# STM32F091CBT6 register map
File version: 1.0
Registers are 32-bit, access not given, reset 0x0 unless marked. A register's access mark holds for its fields unless they carry their own. Offsets are from the block's base; [hi:lo] are bit positions; {n}, {i} and the like mark numbered series.

## CEC
Base 0x40007800
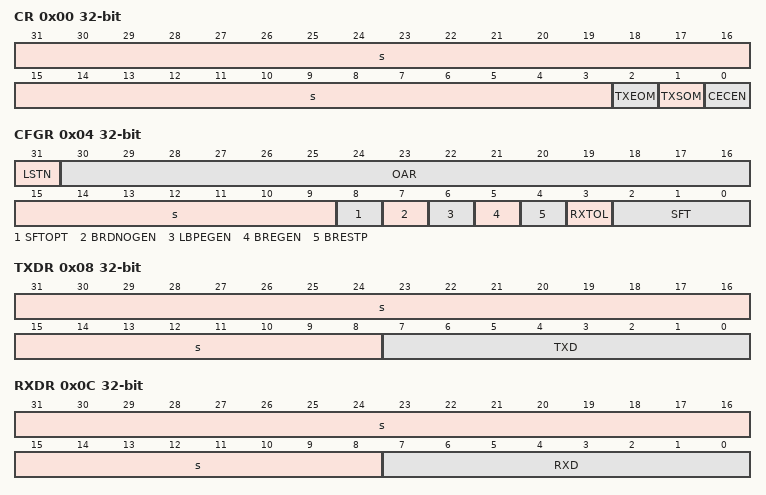
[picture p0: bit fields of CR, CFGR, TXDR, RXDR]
0x00 CR
  [31:3] s, [2] TXEOM, [1] TXSOM, [0] CECEN
0x04 CFGR
  [31] LSTN, [30:16] OAR, [15:9] s, [8] SFTOPT, [7] BRDNOGEN, [6] LBPEGEN, [5] BREGEN, [4] BRESTP, [3] RXTOL, [2:0] SFT
0x08 TXDR
  [31:8] s, [7:0] TXD
0x0C RXDR
  [31:8] s, [7:0] RXD
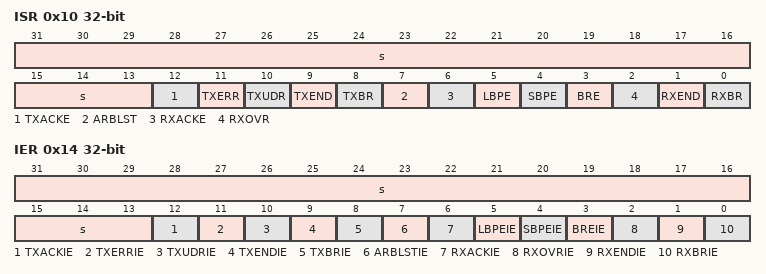
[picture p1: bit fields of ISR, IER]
0x10 ISR
  [31:13] s, [12] TXACKE, [11] TXERR, [10] TXUDR, [9] TXEND, [8] TXBR, [7] ARBLST, [6] RXACKE, [5] LBPE, [4] SBPE, [3] BRE, [2] RXOVR, [1] RXEND, [0] RXBR
0x14 IER
  [31:13] s, [12] TXACKIE, [11] TXERRIE, [10] TXUDRIE, [9] TXENDIE, [8] TXBRIE, [7] ARBLSTIE, [6] RXACKIE, [5] LBPEIE, [4] SBPEIE, [3] BREIE, [2] RXOVRIE, [1] RXENDIE, [0] RXBRIE

## SYSCFGCOMP
Base 0x40010000
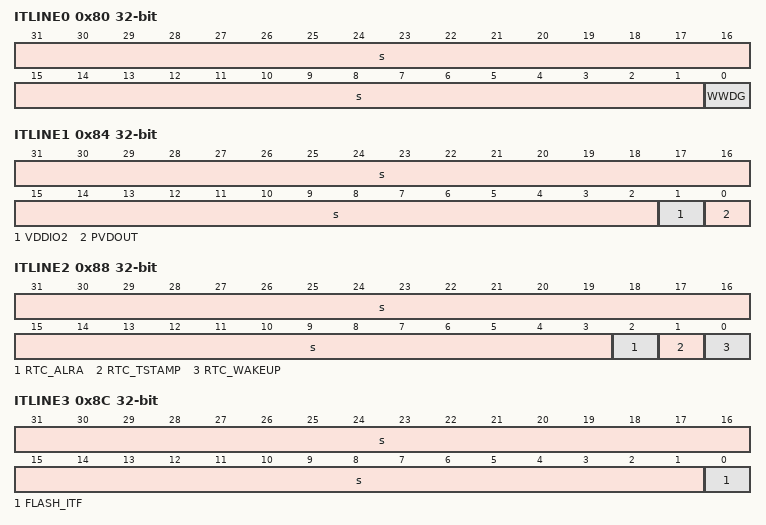
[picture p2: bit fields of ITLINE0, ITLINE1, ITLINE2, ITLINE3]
0x80 ITLINE0
  [31:1] s, [0] WWDG
0x84 ITLINE1
  [31:2] s, [1] VDDIO2, [0] PVDOUT
0x88 ITLINE2
  [31:3] s, [2] RTC_ALRA, [1] RTC_TSTAMP, [0] RTC_WAKEUP
0x8C ITLINE3
  [31:1] s, [0] FLASH_ITF
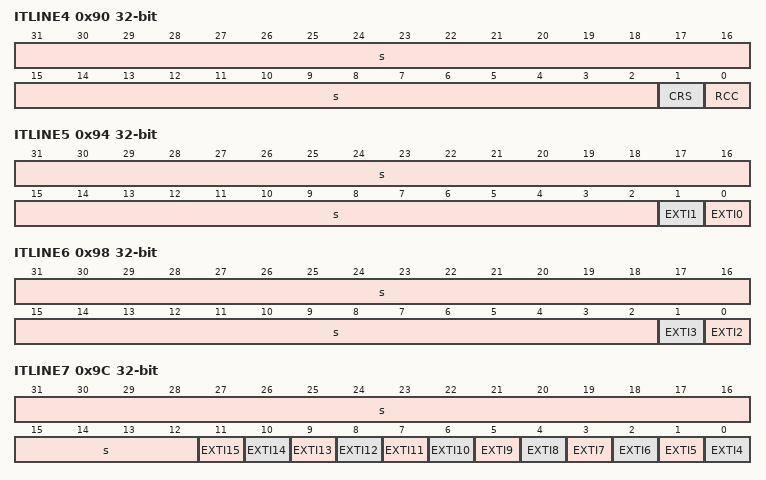
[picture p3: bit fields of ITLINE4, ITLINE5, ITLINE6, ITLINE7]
0x90 ITLINE4
  [31:2] s, [1] CRS, [0] RCC
0x94 ITLINE5
  [31:2] s, [1] EXTI1, [0] EXTI0
0x98 ITLINE6
  [31:2] s, [1] EXTI3, [0] EXTI2
0x9C ITLINE7
  [31:12] s, [n-4] EXTI{n} (n=4..15)
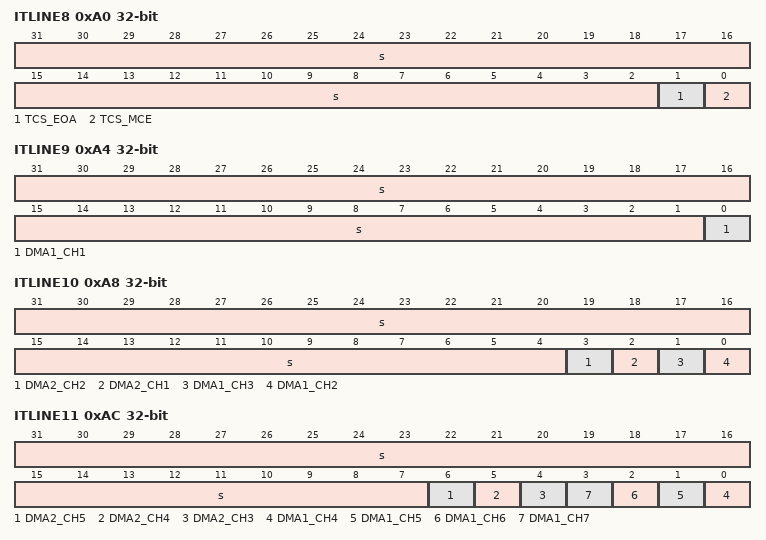
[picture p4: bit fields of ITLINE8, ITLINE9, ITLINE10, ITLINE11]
0xA0 ITLINE8
  [31:2] s, [1] TCS_EOA, [0] TCS_MCE
0xA4 ITLINE9
  [31:1] s, [0] DMA1_CH1
0xA8 ITLINE10
  [31:4] s, [3] DMA2_CH2, [2] DMA2_CH1, [1] DMA1_CH3, [0] DMA1_CH2
0xAC ITLINE11
  [31:7] s, [6] DMA2_CH5, [5] DMA2_CH4, [4] DMA2_CH3, [n-4] DMA1_CH{n} (n=4..7)
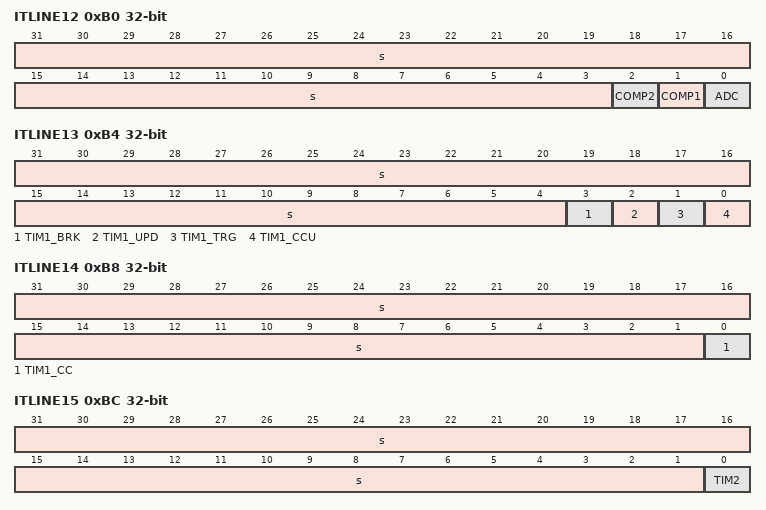
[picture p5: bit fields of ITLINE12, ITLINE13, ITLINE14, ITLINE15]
0xB0 ITLINE12
  [31:3] s, [2] COMP2, [1] COMP1, [0] ADC
0xB4 ITLINE13
  [31:4] s, [3] TIM1_BRK, [2] TIM1_UPD, [1] TIM1_TRG, [0] TIM1_CCU
0xB8 ITLINE14
  [31:1] s, [0] TIM1_CC
0xBC ITLINE15
  [31:1] s, [0] TIM2
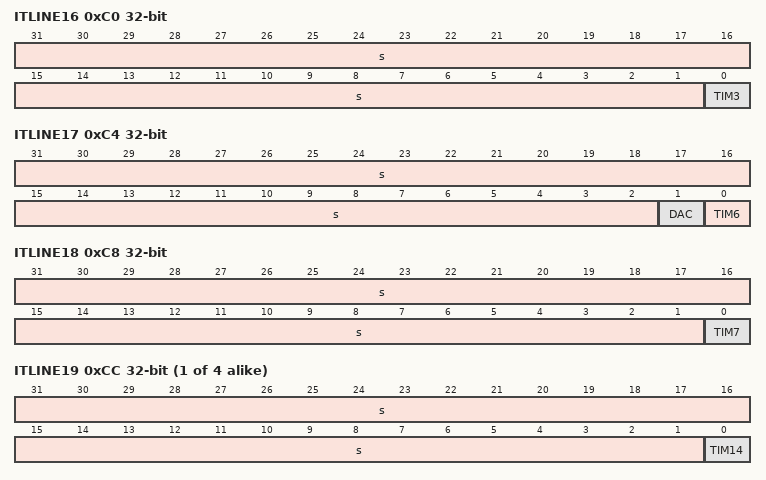
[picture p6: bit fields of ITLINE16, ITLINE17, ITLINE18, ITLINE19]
0xC0 ITLINE16
  [31:1] s, [0] TIM3
0xC4 ITLINE17
  [31:2] s, [1] DAC, [0] TIM6
0xC8 ITLINE18
  [31:1] s, [0] TIM7
{0x80+4i} ITLINE{i} (i=19..22)
  [31:1] s, [0] TIM{i-5}
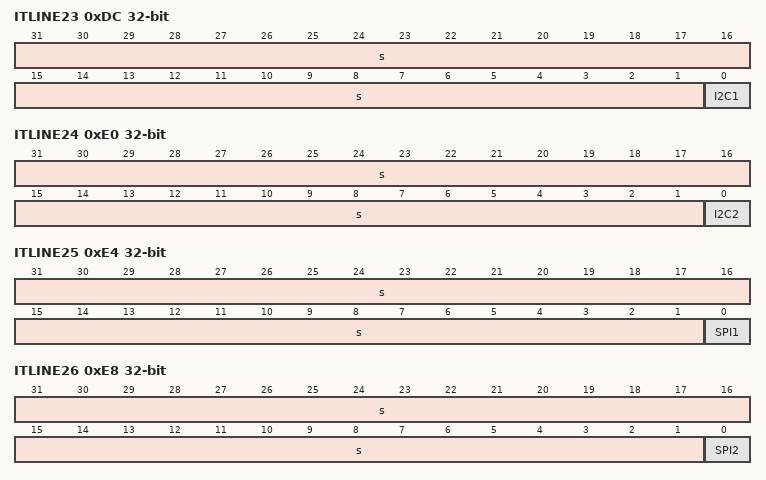
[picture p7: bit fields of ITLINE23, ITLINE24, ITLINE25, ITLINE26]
0xDC ITLINE23
  [31:1] s, [0] I2C1
0xE0 ITLINE24
  [31:1] s, [0] I2C2
0xE4 ITLINE25
  [31:1] s, [0] SPI1
0xE8 ITLINE26
  [31:1] s, [0] SPI2
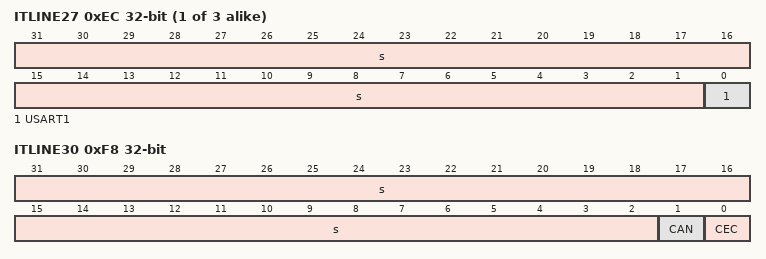
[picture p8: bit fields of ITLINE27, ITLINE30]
{0x80+4i} ITLINE{i} (i=27..29)
  [31:1] s, [0] USART{i-26}
0xF8 ITLINE30
  [31:2] s, [1] CAN, [0] CEC

## EXTI
Base 0x40010400
0x00 IMR
  [31:0] IM
0x04 EMR
  [31:0] EM
0x08 RTSR
  [31] RT31, [n] RT{n} (n=19..23), [30:18] s, [17:0] RT
0x0C FTSR
  [31] FT31, [n] FT{n} (n=19..23), [30:18] s, [17:0] FT
0x10 SWIER
  [31] SWI31, [n] SWI{n} (n=19..23), [30:18] s, [17:0] SWI
0x14 PR
  [31] PIF31, [n] PIF{n} (n=19..23), [30:18] s, [17:0] PIF

## ADC
Base 0x40012400
0x00 ISR
  [7] AWD, [31:5] s, [4] OVR, [3] EOSEQ, [2] EOC, [1] EOSMP, [0] ADRDY
0x04 IER
  [7] AWDIE, [31:5] s, [4] OVRIE, [3] EOSEQIE, [2] EOCIE, [1] EOSMPIE, [0] ADRDYIE
0x08 CR
  [31] ADCAL, [4] ADSTP, [30:3] s, [2] ADSTART, [1] ADDIS, [0] ADEN
0x0C CFGR1
  [30:26] AWDCH, [23] AWDEN, [22] AWDSGL, [16] DISCEN, [15] AUTOFF, [14] WAIT, [13] CONT, [12] OVRMOD, [11:10] EXTEN, [31:9] s, [8:6] EXTSEL, [5] ALIGN, [4:3] RES, [2] SCANDIR, [1] DMACFG, [0] DMAEN
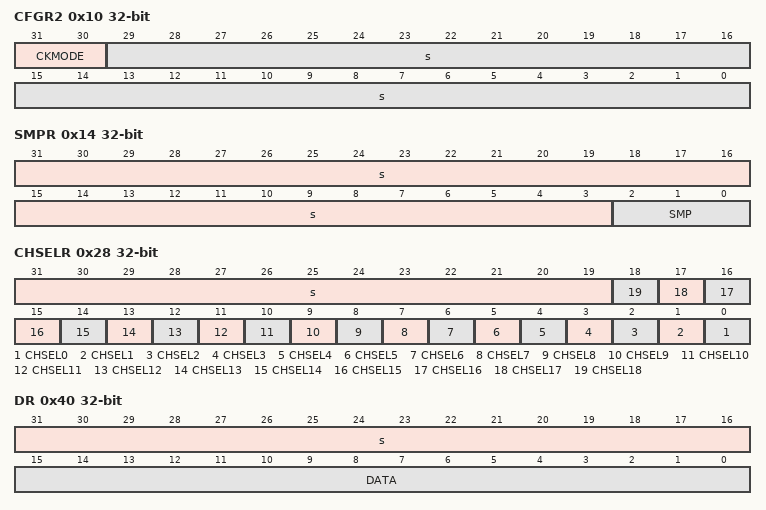
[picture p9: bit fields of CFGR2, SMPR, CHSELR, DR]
0x10 CFGR2
  [31:30] CKMODE, [29:0] s
0x14 SMPR
  [31:3] s, [2:0] SMP
0x20 TR
  [27:16] HT, [31:12] s, [11:0] LT
0x28 CHSELR
  [31:19] s, [n] CHSEL{n} (n=0..18)
0x40 DR
  [31:16] s, [15:0] DATA
0x308 CCR
  [24] VBATEN, [23] TSEN, [22] VREFEN, [31:0] s

## TIM1
Base 0x40012C00
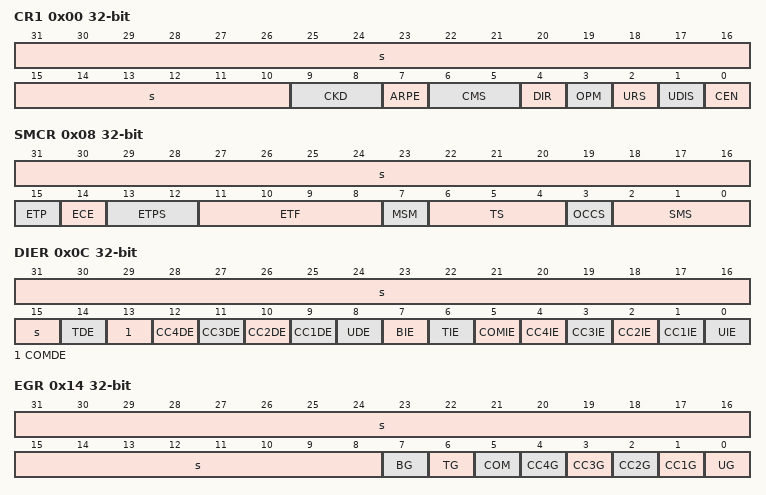
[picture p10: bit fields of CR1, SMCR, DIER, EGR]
0x00 CR1
  [31:10] s, [9:8] CKD, [7] ARPE, [6:5] CMS, [4] DIR, [3] OPM, [2] URS, [1] UDIS, [0] CEN
0x04 CR2
  [2n+6] OIS{n} (n=1..4), [13] OIS3N, [11] OIS2N, [9] OIS1N, [7] TI1S, [6:4] MMS, [3] CCDS, [2] CCUS, [31:1] s, [0] CCPC
0x08 SMCR
  [31:16] s, [15] ETP, [14] ECE, [13:12] ETPS, [11:8] ETF, [7] MSM, [6:4] TS, [3] OCCS, [2:0] SMS
0x0C DIER
  [31:15] s, [14] TDE, [13] COMDE, [n+8] CC{n}DE (n=1..4), [8] UDE, [7] BIE, [6] TIE, [5] COMIE, [n] CC{n}IE (n=1..4), [0] UIE
0x10 SR
  [n+8] CC{n}OF (n=1..4), [31:8] s, [7] BIF, [6] TIF, [5] COMIF, [n] CC{n}IF (n=1..4), [0] UIF
0x14 EGR
  [31:8] s, [7] BG, [6] TG, [5] COM, [n] CC{n}G (n=1..4), [0] UG
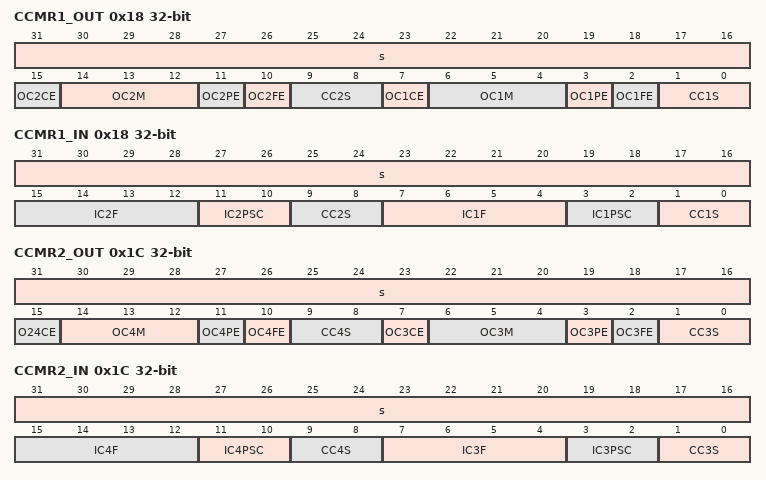
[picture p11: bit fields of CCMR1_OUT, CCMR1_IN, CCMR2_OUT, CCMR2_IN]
0x18 CCMR1_OUT
  [31:16] s, [15] OC2CE, [14:12] OC2M, [11] OC2PE, [10] OC2FE, [9:8] CC2S, [7] OC1CE, [6:4] OC1M, [3] OC1PE, [2] OC1FE, [1:0] CC1S
0x18 CCMR1_IN
  [31:16] s, [15:12] IC2F, [11:10] IC2PSC, [9:8] CC2S, [7:4] IC1F, [3:2] IC1PSC, [1:0] CC1S
0x1C CCMR2_OUT
  [31:16] s, [15] O24CE, [14:12] OC4M, [11] OC4PE, [10] OC4FE, [9:8] CC4S, [7] OC3CE, [6:4] OC3M, [3] OC3PE, [2] OC3FE, [1:0] CC3S
0x1C CCMR2_IN
  [31:16] s, [15:12] IC4F, [11:10] IC4PSC, [9:8] CC4S, [7:4] IC3F, [3:2] IC3PSC, [1:0] CC3S
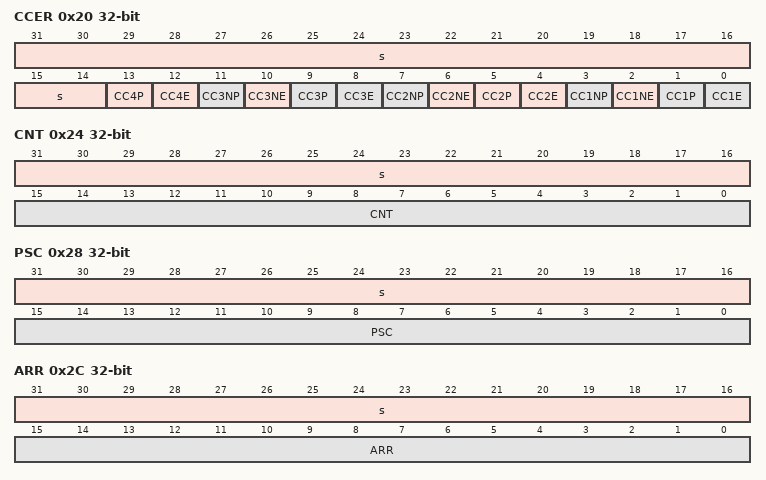
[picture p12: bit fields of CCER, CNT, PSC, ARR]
0x20 CCER
  [31:14] s, [4n-3] CC{n}P (n=1..4), [4n-4] CC{n}E (n=1..4), [11] CC3NP, [10] CC3NE, [7] CC2NP, [6] CC2NE, [3] CC1NP, [2] CC1NE
0x24 CNT
  [31:16] s, [15:0] CNT
0x28 PSC
  [31:16] s, [15:0] PSC
0x2C ARR
  [31:16] s, [15:0] ARR
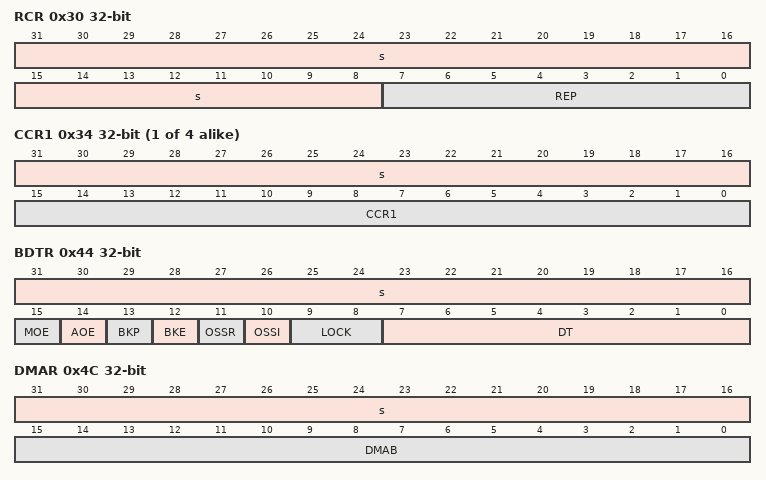
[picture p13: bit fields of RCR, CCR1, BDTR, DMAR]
0x30 RCR
  [31:8] s, [7:0] REP
{0x30+4i} CCR{i} (i=1..4)
  [31:16] s, [15:0] CCR{i}
0x44 BDTR
  [31:16] s, [15] MOE, [14] AOE, [13] BKP, [12] BKE, [11] OSSR, [10] OSSI, [9:8] LOCK, [7:0] DT
0x48 DCR
  [12:8] DBL, [31:5] s, [4:0] DBA
0x4C DMAR
  [31:16] s, [15:0] DMAB
